# STM32U3B5xx register map
File version: 1.0
Registers are 32-bit, read-write, reset 0x0 unless marked. A register's access mark holds for its fields unless they carry their own. Offsets are from the block's base; [hi:lo] are bit positions; {n}, {i} and the like mark numbered series; <NAME> marks a mode.

## I3C1 — Improved Inter-integrated Circuit Interface
Base 0x40005C00
Same registers: I3C2 0x40016C00
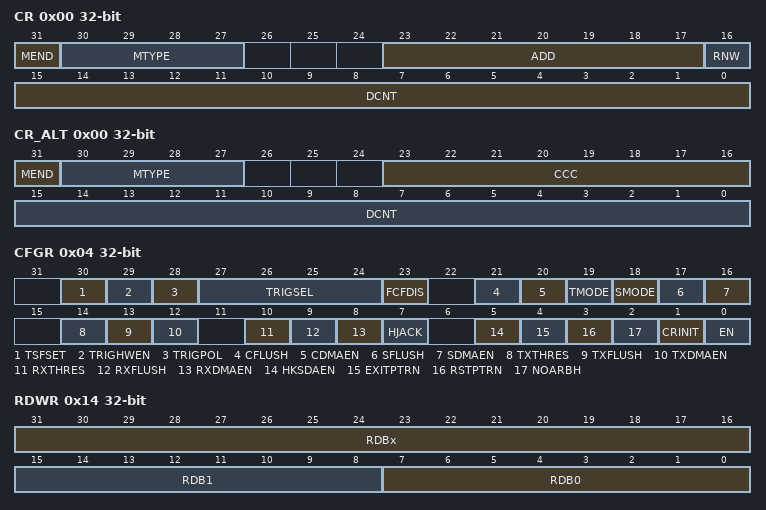
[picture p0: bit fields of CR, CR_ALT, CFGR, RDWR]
0x00 CR — I3C Control register
  [31] MEND — Message End
  [30:27] MTYPE — Message Type
  [23:17] ADD — Target Address
  [16] RNW — Read Not Write
  [15:0] DCNT — Data Byte Count
0x00 CR_ALT (alternate view of CR) — I3C Control register
  [31] MEND — Message End
  [30:27] MTYPE — Message Type
  [23:16] CCC — 8-Bit CCC code
  [15:0] DCNT — Data Byte Count
0x04 CFGR — I3C Controller Configuration register
  [30] TSFSET — Transfer Set
  [29] TRIGHWEN — Trigger enable
  [28] TRIGPOL — Trigger polarity
    0=LOW (Trigger is active when signal is 0); 1=HIGH (Trigger is active when signal is 1)
  [27:24] TRIGSEL — Trigger selection
  [23] FCFDIS — FCF generation disable
    1=DISABLE; 0=ENABLE
  [21] CFLUSH — Control FIFO Flush
  [20] CDMAEN — Control FIFO DMA mode Enable
  [19] TMODE — Control FIFO mode Enable
  [18] SMODE — Status FIFO mode Enable
  [17] SFLUSH — Status FIFO Flush
  [16] SDMAEN — Status FIFO DMA mode Enable
  [14] TXTHRES — TX FIFO Threshold
    0=THRESHOLD_1_4; 1=THRESHOLD_4_4
  [13] TXFLUSH — TX FIFO Flush
  [12] TXDMAEN — TX FIFO DMA mode Enable
  [10] RXTHRES — RX FIFO Threshold
    0=THRESHOLD_1_4; 1=THRESHOLD_4_4
  [9] RXFLUSH — RX FIFO Flush
  [8] RXDMAEN — RX FIFO DMA mode Enable
  [7] HJACK — Hot Join Acknowledgment
  [5] HKSDAEN — High-Keeper on SDA Enable
  [4] EXITPTRN — Exit Pattern enable
  [3] RSTPTRN — Reset Pattern enable
  [2] NOARBH — No Arbitration Header (7'h7E)
  [1] CRINIT — Peripheral Init mode (Target/Controller)
    1=CONTROLLER (I3C Controller mode); 0=TARGET (I3C Target (Controller capable) mode)
  [0] EN — Peripheral Enable
0x10 RDR — I3C Received Data register
  [7:0] RDB0 — Receive Data Byte
0x14 RDWR — I3C Received Data Word register
  [31:16] RDBx — Receive Data Byte, full double word
  [15:8] RDB1 — Receive Data Byte 1
  [7:0] RDB0 — Receive Data Byte 0
0x18 TDR — I3C Transmit Data register
  [7:0] TDB0 — Transmit Data Byte
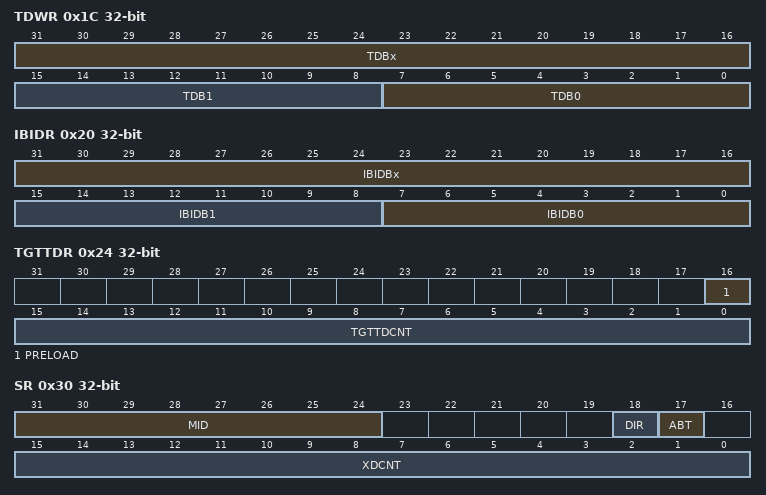
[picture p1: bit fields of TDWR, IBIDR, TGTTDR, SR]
0x1C TDWR — I3C Transmit Data Word register
  [31:16] TDBx — Transmit Data Byte, full double word
  [15:8] TDB1 — Transmit Data Byte 1
  [7:0] TDB0 — Transmit Data Byte 0
0x20 IBIDR — I3C IBI payload Data register
  [31:16] IBIDBx — IBI Data Byte, full double word
  [15:8] IBIDB1 — IBI Data Byte 1
  [7:0] IBIDB0 — IBI Data Byte 0
0x24 TGTTDR — I3C Target Transmit register
  [16] PRELOAD — Transmit FIFO Preload Enable/Status
  [15:0] TGTTDCNT — Target Transmit Data Counter
0x30 SR — I3C Status register
  [31:24] MID — Message Identifier
  [18] DIR — Message Direction
    0=WRITE (Write data or command); 1=READ (Read data)
  [17] ABT — Target Abort Indication
  [15:0] XDCNT — Transfer Data Byte Count status
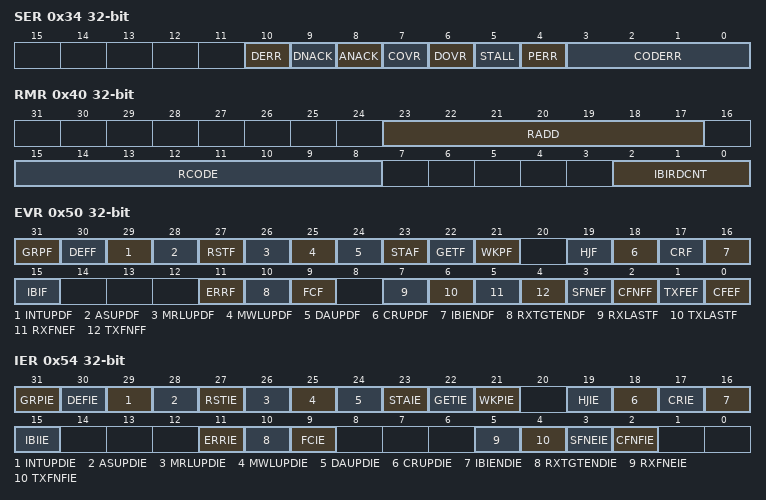
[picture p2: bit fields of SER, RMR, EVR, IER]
0x34 SER — I3C Status Error register
  [10] DERR — Data Error during the controller-role hand-off procedure
  [9] DNACK — Data Not Acknowledged
  [8] ANACK — Address Not Acknowledged
  [7] COVR — Status/Control FIFO Overrun
  [6] DOVR — RX/TX FIFO Overrun
  [5] STALL — SCL Stall Error
  [4] PERR — Protocol Error
  [3:0] CODERR — Protocol Error Code
    {v}=CONTROLLER_ERROR_CE{v} (v=0..3); {v}=TARGET_ERROR_TE{v-8} (v=8..14)
0x40 RMR — I3C Received Message register
  [23:17] RADD — Target Address Received during accepted IBI or Controller-role request
  [15:8] RCODE — CCC code of received command
  [2:0] IBIRDCNT — Data Count when reading IBI data
0x50 EVR — I3C Event register
  [31] GRPF — List of Group Addresses Command Received Flag
  [30] DEFF — List of Targets Command Received Flag
  [29] INTUPDF — Interrupt Update Flag
  [28] ASUPDF — Activity State Flag
  [27] RSTF — Reset Flag, due to Reset pattern received
  [26] MRLUPDF — Max Read Length Update Flag
  [25] MWLUPDF — Max Write Length Update Flag
  [24] DAUPDF — Dynamic Address Update Flag
  [23] STAF — Get Status Flag
  [22] GETF — Get type CCC received Flag
  [21] WKPF — Wake Up Flag
  [19] HJF — Hot Join Flag
  [18] CRUPDF — Controller-role Update Flag
  [17] CRF — Controller-role Request Flag
  [16] IBIENDF — IBI End Flag
  [15] IBIF — IBI Flag
  [11] ERRF — Error Flag
  [10] RXTGTENDF — Reception Target End Flag
  [9] FCF — Frame Complete Flag
  [7] RXLASTF — Last RX byte read from FIFO
  [6] TXLASTF — Last TX byte available in FIFO
  [5] RXFNEF — RX FIFO Not Empty Flag
  [4] TXFNFF — TX FIFO Not Full Flag
  [3] SFNEF — Status FIFO Not Empty Flag
  [2] CFNFF — Control FIFO Not Full Flag
  [1] TXFEF — TX FIFO Empty Flag
  [0] CFEF — Control FIFO Empty Flag
0x54 IER — I3C Interrupt Enable register
  [31] GRPIE — List of Group Addresses Command Received Interrupt Enable
  [30] DEFIE — List of Targets Command Received Interrupt Enable
  [29] INTUPDIE — Interrupt Update Interrupt Enable
  [28] ASUPDIE — Activity State Interrupt Enable
  [27] RSTIE — Reset Interrupt Enabled, due to Reset pattern received
  [26] MRLUPDIE — Max Read Length Update Interrupt Enable
  [25] MWLUPDIE — Max Write Length Update Interrupt Enable
  [24] DAUPDIE — Dynamic Address Update Interrupt Enable
  [23] STAIE — Get Status Interrupt Enable
  [22] GETIE — Get type CCC received Interrupt Enable
  [21] WKPIE — Wake Up Interrupt Enable
  [19] HJIE — Hot Join Interrupt Enable
  [18] CRUPDIE — Controller-role Update Interrupt Enable
  [17] CRIE — Controller-role Interrupt Enable
  [16] IBIENDIE — IBI End Interrupt Enable
  [15] IBIIE — IBI Interrupt Enable
  [11] ERRIE — Error Interrupt Enable
  [10] RXTGTENDIE — Reception Target End Interrupt Enable
  [9] FCIE — Frame Complete Interrupt Enable
  [5] RXFNEIE — RX FIFO Not Empty Interrupt Enable
  [4] TXFNFIE — TX FIFO Not Full Interrupt Enable
  [3] SFNEIE — Status FIFO Not Empty Interrupt Enable
  [2] CFNFIE — Control FIFO Not Full Interrupt Enable
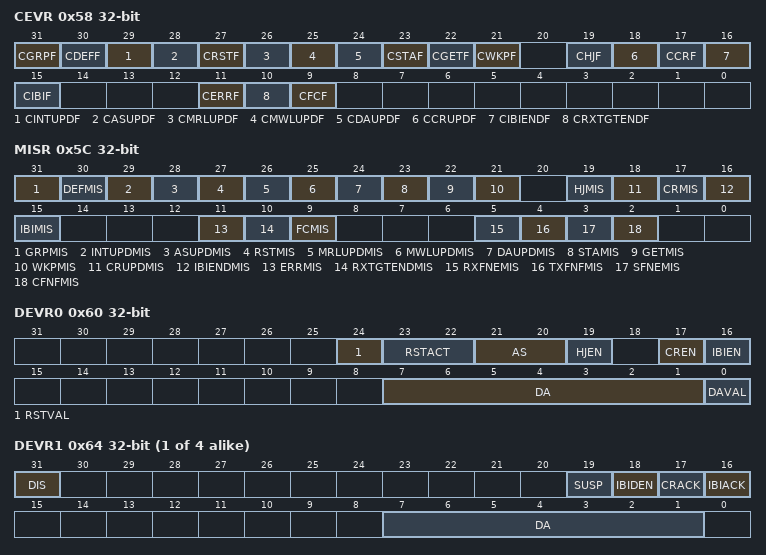
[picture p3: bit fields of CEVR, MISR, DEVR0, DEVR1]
0x58 CEVR — I3C Clear Event register
  [31] CGRPF — List of Group Addresses Command Received Clear Flag
  [30] CDEFF — List of Targets Command Received Clear Flag
  [29] CINTUPDF — Interrupt Update Clear Flag
  [28] CASUPDF — Activity State Clear Flag
  [27] CRSTF — Reset Flag, due to Reset pattern received
  [26] CMRLUPDF — Max Read Length Update Clear Flag
  [25] CMWLUPDF — Max Write Length Update Clear Flag
  [24] CDAUPDF — Dynamic Address Update Clear Flag
  [23] CSTAF — Get Status Clear Flag
  [22] CGETF — Get type CCC received Clear Flag
  [21] CWKPF — Wake Up Clear Flag
  [19] CHJF — Hot Join Clear Flag
  [18] CCRUPDF — Controller-role Update Clear Flag
  [17] CCRF — Controller-role Clear Flag
  [16] CIBIENDF — IBI End Clear Flag
  [15] CIBIF — IBI Clear Flag
  [11] CERRF — Error Clear Flag
  [10] CRXTGTENDF — Reception Target End Clear Flag
  [9] CFCF — Frame Complete Clear Flag
0x5C MISR — I3C Masked Interrupt Status register
  [31] GRPMIS — List of Group Addresses Command Received Mask Interrupt Status
  [30] DEFMIS — List of Targets Command Received Mask Interrupt Status
  [29] INTUPDMIS — Interrupt Update Mask Interrupt Status
  [28] ASUPDMIS — Activity State Mask Interrupt Status
  [27] RSTMIS — Reset Mask Interrupt Status, due to Reset pattern received
  [26] MRLUPDMIS — Max Read Length Update Mask Interrupt Status
  [25] MWLUPDMIS — Max Write Length Update Mask Interrupt Status
  [24] DAUPDMIS — Dynamic Address Update Mask Interrupt Status
  [23] STAMIS — Get Status Mask Interrupt Status
  [22] GETMIS — Get type CCC received Mask Interrupt Status
  [21] WKPMIS — Wake Up Mask Interrupt Status
  [19] HJMIS — Hot Join Mask Interrupt Status
  [18] CRUPDMIS — Controller-role Update Mask Interrupt Status
  [17] CRMIS — Controller-role Mask Interrupt Status
  [16] IBIENDMIS — IBI End Mask Interrupt Status
  [15] IBIMIS — IBI Mask Interrupt Status
  [11] ERRMIS — Error Mask Interrupt Status
  [10] RXTGTENDMIS — Reception Target End Mask Interrupt Status
  [9] FCMIS — Frame Complete Mask Interrupt Status
  [5] RXFNEMIS — RX FIFO Not Empty Mask Interrupt Status
  [4] TXFNFMIS — TX FIFO Not Full Mask Interrupt Status
  [3] SFNEMIS — Status FIFO Not Empty Mask Interrupt Status
  [2] CFNFMIS — Control FIFO Not Full Mask Interrupt Status
0x60 DEVR0 — I3C own Target characteristics register
  [24] RSTVAL — Reset Action Valid
  [23:22] RSTACT — Reset Action value update after RSTACT received
    0=NONE; 1=PARTIAL; 2=FULL
  [21:20] AS — Activity State value update after ENTAx received
    {v}=STATE_{v} (v=0..3)
  [19] HJEN — Hot Join Enable
  [17] CREN — Controller-role Enable
  [16] IBIEN — IBI Enable
  [7:1] DA — Own Target Device Address
  [0] DAVAL — Dynamic Address Validity
{0x60+4i} DEVR{i} (i=1..4) — I3C Target x (1<=x<=4) register
  [31] DIS — Disable Register access
  [19] SUSP — Suspended Transfer
  [18] IBIDEN — IBI Additional Data Enable
  [17] CRACK — Controller-role Acknowledge from Target x
  [16] IBIACK — IBI Acknowledge from Target x
  [7:1] DA — Dynamic Address Target x
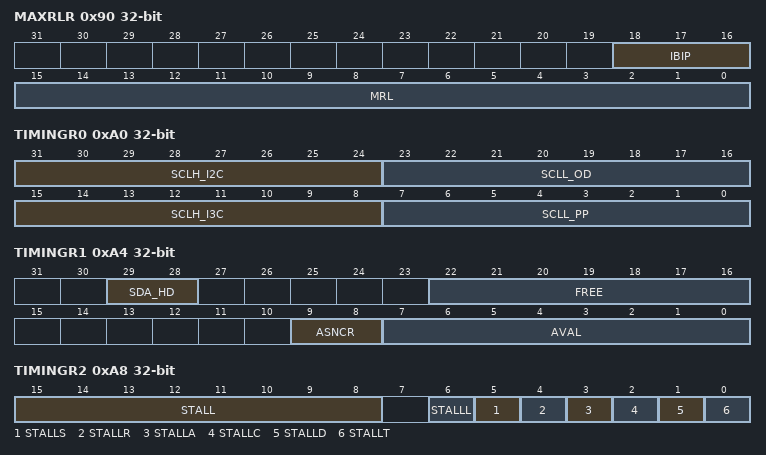
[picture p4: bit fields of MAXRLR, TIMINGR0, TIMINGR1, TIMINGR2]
0x90 MAXRLR — I3C Maximum Read Length register
  [18:16] IBIP — IBI Payload size
    0=EMPTY; 1=PAYLOAD_1_BYTE; 2=PAYLOAD_2_BYTES; 3=PAYLOAD_3_BYTES; 4=PAYLOAD_4_BYTES
  [15:0] MRL — Maximum Read Length
0x94 MAXWLR — I3C Maximum Write Length register
  [15:0] MWL — Maximum Write Length
0xA0 TIMINGR0 — I3C Timing 0 register
  [31:24] SCLH_I2C — SCL High duration during I2C transfer
  [23:16] SCLL_OD — SCL Low duration during I3C Open-drain phases and I2C transfer
  [15:8] SCLH_I3C — SCL High duration during I3C Open-drain and Push-Pull phases
  [7:0] SCLL_PP — SCL Low duration during I3C Push-Pull phases
0xA4 TIMINGR1 — I3C Timing 1 register
  [29:28] SDA_HD — SDA Hold Duration
    {v}=TIME_{v}_5 (v=0..3)
  [22:16] FREE — Timing for I3C Bus Free condition
  [9:8] ASNCR — Activity State of the New Controller
    {v}=STATE_{v} (v=0..3)
  [7:0] AVAL — Timing for I3C Bus Idle or Available condition
0xA8 TIMINGR2 — I3C Timing 2 register
  [15:8] STALL — Controller Stall duration
  [6] STALLL — Stall on I2C Address ACK bit
  [5] STALLS — Stall on I2C Write ACK bit
  [4] STALLR — Stall on I2C Read ACK bit
  [3] STALLA — Stall on ACK bit
  [2] STALLC — Stall on PAR bit of CCC byte
  [1] STALLD — Stall on PAR bit of data bytes
  [0] STALLT — Stall on T bit
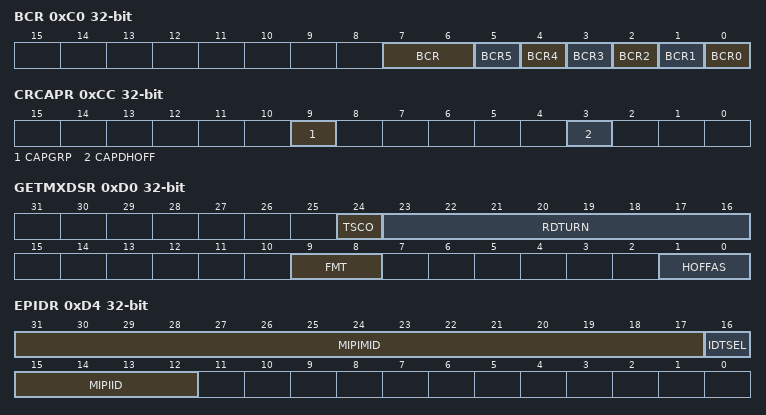
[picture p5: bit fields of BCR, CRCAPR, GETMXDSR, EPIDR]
0xC0 BCR — I3C Bus Characteristics register
  [7:6] BCR — Bus Characteristics
  [5] BCR5 — Advanced capabilities
  [4] BCR4 — Virtual target support
  [3] BCR3 — Offline capable
  [2] BCR2 — IBI Payload additional Mandatory Data Byte
    0=NO_ADDITIONAL_DATA (No data byte follows the accepted IBI); 1=ADDITIONAL_DATA
  [1] BCR1 — IBI Request capable
  [0] BCR0 — Max Data Speed Limitation
    0=NO_DATA_SPEED_LIMITATION (No max data speed limitation); 1=MAX_DATA_SPEED_LIMITATION
0xC4 DCR — I3C Device Characteristics register
  [7:0] DCR — Devices Characteristics
0xC8 GETCAPR — I3C GET CAPabilities register
  [14] CAPPEND — IBI Request with Mandatory Data Byte
    0=NO_PENDING_READ_NOTIFICATION; 1=PENDING_READ_NOTIFICATION
0xCC CRCAPR — I3C Controller CAPabilities register
  [9] CAPGRP — Group Address handoff supported
    0=NOT_SUPPORTED (Group Address Handoff is not supported); 1=SUPPORTED (Group Address Handoff is supported)
  [3] CAPDHOFF — Controller-role handoff needed
    0=NOT_DELAYED; 1=DELAYED
0xD0 GETMXDSR — I3C GET Max Data Speed register
  [24] TSCO — Clock-to-data Turnaround time
    0=LESS_12NS (clock-to-data turnaround time tSCO <= 12ns); 1=GREATER_12NS (clock-to-data turnaround time tSCO > 12ns)
  [23:16] RDTURN — Max Read Turnaround Middle Byte
  [9:8] FMT — Get Max Data Speed response in format 2
    0=FORMAT_1; 1=FORMAT_2_LSB; 2=FORMAT_2_MID; 3=FORMAT_2_MSB
  [1:0] HOFFAS — Handoff Activity State
    {v}=STATE_{v} (v=0..3)
0xD4 EPIDR — I3C Extended Provisioned ID register
  [31:17] MIPIMID — MIPI Manufacturer ID
  [16] IDTSEL — ID Type Selector
  [15:12] MIPIID — MIPI Instance ID
